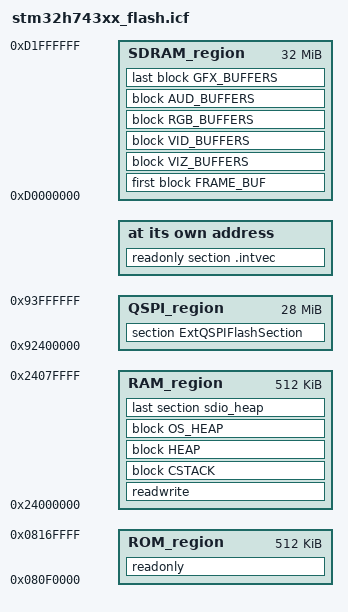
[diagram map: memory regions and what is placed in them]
/*###ICF### Section handled by ICF editor, don't touch! ****/
/*-Editor annotation file-*/
/* IcfEditorFile="$TOOLKIT_DIR$\config\ide\IcfEditor\cortex_v1_0.xml" */
/*-Specials-*/
define symbol __ICFEDIT_intvec_start__ = __C_START_ADDR;
/*-Memory Regions-*/
define symbol __ICFEDIT_region_ROM_start__     = 0x080F0000;
define symbol __ICFEDIT_region_ROM_end__       = 0x0816FFFF;
define symbol __ICFEDIT_region_RAM_start__     = 0x24000000;
define symbol __ICFEDIT_region_RAM_end__       = 0x2407FFFF;
/*-Sizes-*/
define symbol __ICFEDIT_size_cstack__ = 0x3000;
define symbol __ICFEDIT_size_heap__   = 0x7000;
/**** End of ICF editor section. ###ICF###*/

/*-External RAM Memory Regions-*/
define symbol __ICFEDIT_region_SDRAM_start__ = 0xD0000000;   /*  32 Mbytes */
define symbol __ICFEDIT_region_SDRAM_end__   = 0xD1FFFFFF;

define symbol __ICFEDIT_region_QSPI_start__ = 0x92400000;
define symbol __ICFEDIT_region_QSPI_end__   = 0x93FFFFFF;

define memory mem with size = 4G;
define region ROM_region      = mem:[from __ICFEDIT_region_ROM_start__    to __ICFEDIT_region_ROM_end__];
define region RAM_region      = mem:[from __ICFEDIT_region_RAM_start__    to __ICFEDIT_region_RAM_end__];
define region SDRAM_region    = mem:[from __ICFEDIT_region_SDRAM_start__  to __ICFEDIT_region_SDRAM_end__];
define region QSPI_region     = mem:[from __ICFEDIT_region_QSPI_start__   to __ICFEDIT_region_QSPI_end__];

define block CSTACK    with alignment = 8, size = __ICFEDIT_size_cstack__   { };
define block HEAP      with alignment = 8, size = __ICFEDIT_size_heap__     { };

define block OS_HEAP      with alignment = 32   { first section heap_mem };
define block FRAME_BUF    with alignment = 32   { first section framebuffer };
define block GFX_BUFFERS  with alignment = 32   { first section STemWinMemPool };
define block VIZ_BUFFERS  with alignment = 32   { first section viz_front_buffer, section viz_back_buffer, section viz_deform_x_buffer, section viz_deform_y_buffer, section viz_bitmap_buffer };
define block AUD_BUFFERS  with alignment = 32   { first section audio_buffers };
define block VID_BUFFERS  with alignment = 32   { first section video_buffers };
define block RGB_BUFFERS  with alignment = 32   { first section rgb_video_buffers };

initialize by copy { readwrite };
do not initialize  { section .noinit };
do not initialize  { section framebuffer, section STemWinMemPool };
do not initialize  { section viz_front_buffer, section viz_back_buffer, section viz_deform_x_buffer, section viz_deform_y_buffer, section viz_bitmap_buffer };
do not initialize  { section audio_buffers, section video_buffers, section rgb_video_buffers };

place at address mem:__ICFEDIT_intvec_start__ { readonly section .intvec };

place in ROM_region   { readonly };
place in RAM_region   { readwrite, block CSTACK, block HEAP, block OS_HEAP, last section sdio_heap };
place in SDRAM_region { first block FRAME_BUF, block VIZ_BUFFERS, block VID_BUFFERS, block RGB_BUFFERS, block AUD_BUFFERS, last block GFX_BUFFERS };
place in QSPI_region  { section ExtQSPIFlashSection };
